VERSION ""

NS_ :

BS_:

BU_: FrontLightLeft FrontLightRight DriverSideDoor PassengerSideDoor AmbientLights ZoneControllerFront GearShifter

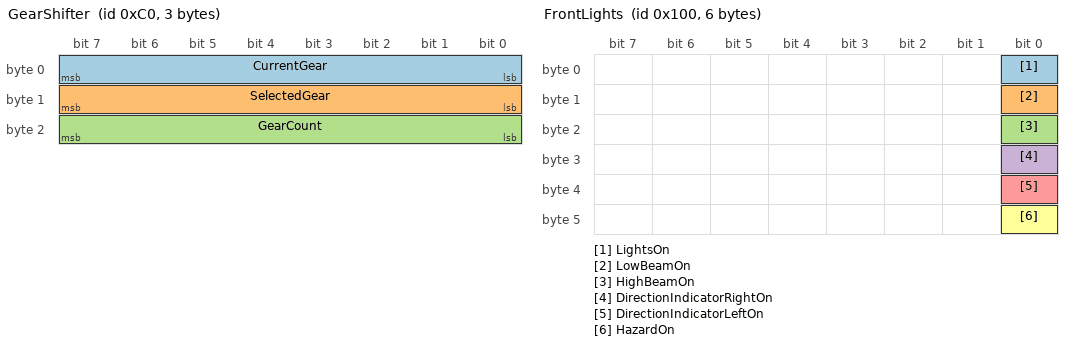
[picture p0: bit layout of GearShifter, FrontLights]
BO_ 192 GearShifter: 3 GearShifter
 SG_ CurrentGear  : 0|8@1- (1,0) [-128|127] "" ZoneControllerFront
 SG_ SelectedGear : 8|8@1- (1,0) [-128|127] "" ZoneControllerFront
 SG_ GearCount    : 16|8@1- (1,0) [-128|127] "" ZoneControllerFront

BO_ 256 FrontLights: 6 ZoneController
 SG_ LightsOn : 0|1@1+ (1,0) [0|1] "" FrontLightLeft,FrontLightRight
 SG_ LowBeamOn : 8|1@1+ (1,0) [0|1] "" FrontLightLeft,FrontLightRight
 SG_ HighBeamOn : 16|1@1+ (1,0) [0|1] "" FrontLightLeft,FrontLightRight
 SG_ DirectionIndicatorRightOn : 24|1@1+ (1,0) [0|1] "" FrontLightRight
 SG_ DirectionIndicatorLeftOn : 32|1@1+ (1,0) [0|1] "" FrontLightLeft
 SG_ HazardOn : 40|1@1+ (1,0) [0|1] "" FrontLightLeft,FrontLightRight

 BO_ 128 Lock: 2 KeylessEntry
 SG_ VehicleDoorLocked : 0|1@1+ (1,0) [0|1] "" ZoneControllerRear

BO_ 80 DriverSideDoorSensor: 1 DriverSideDoor
 SG_ DriverSideDoorOpen : 0|1@1+ (1,0) [0|1] "" PassengerSideDoor,ZoneControllerFront

BO_ 96 PassengerSideDoorSensor: 1 PassengerSideDoor
 SG_ PassengerSideDoorOpen : 0|1@1+ (1,0) [0|1] "" DriverSideDoor,ZoneControllerFront

VAL_ 192 GearCount -1 "CVT";
VAL_ 192 SelectedGear 126 "PARK" 127 "DRIVE" 0 "NEUTRAL";
VAL_ 192 CurrentGear  0 "NEUTRAL";

VAL_ 256 LightsOn 0 "OFF" 1 "ON";
VAL_ 256 LowBeamOn 0 "OFF" 1 "ON";
VAL_ 256 HighBeamOn 0 "OFF" 1 "ON";
VAL_ 256 DirectionIndicatorRightOn 0 "OFF" 1 "ON";
VAL_ 256 DirectionIndicatorLeftOn 0 "OFF" 1 "ON";
VAL_ 256 HazardOn 0 "OFF" 1 "ON";

VAL_ 128 VehicleDoorLocked 0 "UNLOCKED" 1 "LOCKED";

VAL_ 80 DriverSideDoorOpen 0 "CLOSED" 1 "OPEN";

VAL_ 96 PassengerSideDoorOpen 0 "CLOSED" 1 "OPEN";
